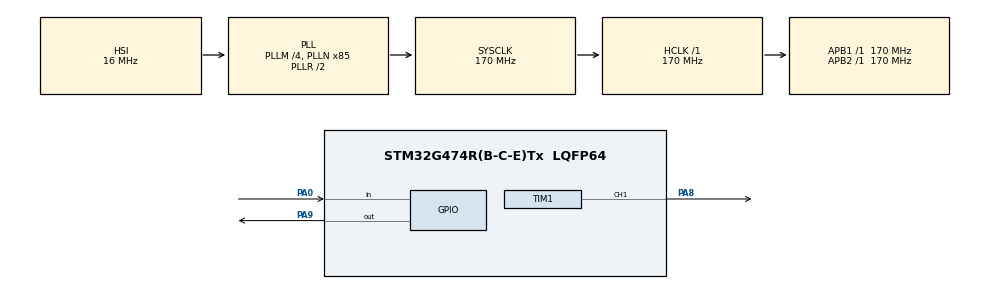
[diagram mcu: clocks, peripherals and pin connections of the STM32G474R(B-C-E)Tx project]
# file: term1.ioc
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Mcu.Family=STM32G4
Mcu.Name=STM32G474R(B-C-E)Tx
Mcu.Package=LQFP64
NVIC.PriorityGroup=NVIC_PRIORITYGROUP_4
PA0.GPIO_PuPd=GPIO_PULLUP
PA0.Signal=GPIO_Input
PA13.GPIO_Label=T_SWDIO
PA13.Signal=SYS_JTMS-SWDIO
PA14.GPIO_Label=T_SWCLK
PA14.Signal=SYS_JTCK-SWCLK
PA2.GPIO_Label=LPUART1_TX [STLINKV3E_VCP_RX]
PA2.Signal=LPUART1_TX
PA3.GPIO_Label=LPUART1_RX [STLINKV3E_VCP_TX]
PA3.Signal=LPUART1_RX
PA8.Signal=S_TIM1_CH1
PA9.Signal=GPIO_Output
PB3.GPIO_Label=T_SWO
PB3.Signal=SYS_JTDO-SWO
PC14-OSC32_IN.GPIO_Label=RCC_OSC32_IN
PC14-OSC32_IN.Signal=RCC_OSC32_IN
PC15-OSC32_OUT.GPIO_Label=RCC_OSC32_OUT
PC15-OSC32_OUT.Signal=RCC_OSC32_OUT
PF0-OSC_IN.GPIO_Label=RCC_OSC_IN
PF0-OSC_IN.Signal=RCC_OSC_IN
PF1-OSC_OUT.GPIO_Label=RCC_OSC_OUT
PF1-OSC_OUT.Signal=RCC_OSC_OUT
ProjectManager.HeapSize=0x200
ProjectManager.StackSize=0x400
ProjectManager.TargetToolchain=STM32CubeIDE
RCC.ADC12Freq_Value=170000000
RCC.ADC345Freq_Value=170000000
RCC.AHBFreq_Value=170000000
RCC.APB1Freq_Value=170000000
RCC.APB1TimFreq_Value=170000000
RCC.APB2Freq_Value=170000000
RCC.APB2TimFreq_Value=170000000
RCC.CortexFreq_Value=170000000
RCC.EXTERNAL_CLOCK_VALUE=12288000
RCC.HCLKFreq_Value=170000000
RCC.HSE_VALUE=24000000
RCC.HSI48_VALUE=48000000
RCC.HSI_VALUE=16000000
RCC.LSE_VALUE=32768
RCC.PLLM=RCC_PLLM_DIV4
RCC.PLLN=85
RCC.RTCClockSelection=RCC_RTCCLKSOURCE_LSE
RCC.SYSCLKFreq_VALUE=170000000
RCC.SYSCLKSource=RCC_SYSCLKSOURCE_PLLCLK
RCC.USBFreq_Value=170000000
RCC.VCOOutputFreq_Value=340000000
SH.S_TIM1_CH1.0=TIM1_CH1,PWM Generation1 CH1
TIM1.Channel-PWM\ Generation1\ CH1=TIM_CHANNEL_1
TIM1.PeriodNoDither=999
TIM1.Prescaler=169
VP_SYS_VS_DBSignals.Mode=DisableDeadBatterySignals
VP_TIM1_VS_ClockSourceINT.Mode=Internal
board=NUCLEO-G474RE

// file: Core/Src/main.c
/* USER CODE BEGIN Header */
/**
  ******************************************************************************
  * @file           : main.c
  * @brief          : Main program body
  ******************************************************************************
  * @attention
  *
  * Copyright (c) 2026 STMicroelectronics.
  * All rights reserved.
  *
  * This software is licensed under terms that can be found in the LICENSE file
  * in the root directory of this software component.
  * If no LICENSE file comes with this software, it is provided AS-IS.
  *
  ******************************************************************************
  */
/* USER CODE END Header */
#include "main.h"

TIM_HandleTypeDef htim1;

/* USER CODE BEGIN PV */
const uint16_t pwm_levels[] = {1000, 750, 500, 250, 100, 0};
uint8_t press_count = 0;
uint8_t last_button_state = GPIO_PIN_SET;
/* USER CODE END PV */

void SystemClock_Config(void);
static void MX_GPIO_Init(void);
static void MX_TIM1_Init(void);

int main(void)
{

  /* MCU Configuration--------------------------------------------------------*/

  /* Reset of all peripherals, Initializes the Flash interface and the Systick. */
  HAL_Init();

  /* Configure the system clock */
  SystemClock_Config();

  /* Initialize all configured peripherals */
  MX_GPIO_Init();
  MX_TIM1_Init();
  /* USER CODE BEGIN 2 */
  // 啟動 TIM1 Channel 1 的 PWM 輸出
  HAL_TIM_PWM_Start(&htim1, TIM_CHANNEL_1);
  // 設定初始亮度為 1000 (全亮)
  __HAL_TIM_SET_COMPARE(&htim1, TIM_CHANNEL_1, pwm_levels[0]);
  /* USER CODE END 2 */

  /* Infinite loop */
    while (1)
    {

      /* USER CODE BEGIN 3 */
      // 讀取 PA0 按鈕狀態
      uint8_t current_button_state = HAL_GPIO_ReadPin(GPIOA, GPIO_PIN_0);

      // 檢測按鈕下緣觸發 (按下瞬間：從 High 變 Low)
      if (last_button_state == GPIO_PIN_SET && current_button_state == GPIO_PIN_RESET)
      {
        HAL_Delay(50); // 防彈跳濾波 (Debounce)
        if (HAL_GPIO_ReadPin(GPIOA, GPIO_PIN_0) == GPIO_PIN_RESET)
        {
          press_count++;

          if (press_count <= 4)
          {
            // 第 1 至 4 次按下：更新 PA8 的 PWM 亮度
            __HAL_TIM_SET_COMPARE(&htim1, TIM_CHANNEL_1, pwm_levels[press_count]);
          }
          else if (press_count == 5)
          {
            // 第 5 次按下：PA8 熄滅，PA9 亮起 (開始澆水)
            __HAL_TIM_SET_COMPARE(&htim1, TIM_CHANNEL_1, pwm_levels[5]); // 0
            HAL_GPIO_WritePin(GPIOA, GPIO_PIN_9, GPIO_PIN_SET);

            // 5 秒內平滑漸亮恢復至 1000 (分 100 階，每階 50ms)
            for (int i = 0; i <= 1000; i += 10)
            {
              __HAL_TIM_SET_COMPARE(&htim1, TIM_CHANNEL_1, i);
              HAL_Delay(50);
            }

            // 澆水完畢：熄滅 PA9，重置計數
            HAL_GPIO_WritePin(GPIOA, GPIO_PIN_9, GPIO_PIN_RESET);
            press_count = 0;
          }
        }
      }

      last_button_state = current_button_state;
    }
    /* USER CODE END 3 */
}

void SystemClock_Config(void)
{
  RCC_OscInitTypeDef RCC_OscInitStruct = {0};
  RCC_ClkInitTypeDef RCC_ClkInitStruct = {0};

  /** Configure the main internal regulator output voltage
  */
  HAL_PWREx_ControlVoltageScaling(PWR_REGULATOR_VOLTAGE_SCALE1_BOOST);

  /** Initializes the RCC Oscillators according to the specified parameters
  * in the RCC_OscInitTypeDef structure.
  */
  RCC_OscInitStruct.OscillatorType = RCC_OSCILLATORTYPE_HSI;
  RCC_OscInitStruct.HSIState = RCC_HSI_ON;
  RCC_OscInitStruct.HSICalibrationValue = RCC_HSICALIBRATION_DEFAULT;
  RCC_OscInitStruct.PLL.PLLState = RCC_PLL_ON;
  RCC_OscInitStruct.PLL.PLLSource = RCC_PLLSOURCE_HSI;
  RCC_OscInitStruct.PLL.PLLM = RCC_PLLM_DIV4;
  RCC_OscInitStruct.PLL.PLLN = 85;
  RCC_OscInitStruct.PLL.PLLP = RCC_PLLP_DIV2;
  RCC_OscInitStruct.PLL.PLLQ = RCC_PLLQ_DIV2;
  RCC_OscInitStruct.PLL.PLLR = RCC_PLLR_DIV2;
  if (HAL_RCC_OscConfig(&RCC_OscInitStruct) != HAL_OK)
  {
    Error_Handler();
  }

  /** Initializes the CPU, AHB and APB buses clocks
  */
  RCC_ClkInitStruct.ClockType = RCC_CLOCKTYPE_HCLK|RCC_CLOCKTYPE_SYSCLK
                              |RCC_CLOCKTYPE_PCLK1|RCC_CLOCKTYPE_PCLK2;
  RCC_ClkInitStruct.SYSCLKSource = RCC_SYSCLKSOURCE_PLLCLK;
  RCC_ClkInitStruct.AHBCLKDivider = RCC_SYSCLK_DIV1;
  RCC_ClkInitStruct.APB1CLKDivider = RCC_HCLK_DIV1;
  RCC_ClkInitStruct.APB2CLKDivider = RCC_HCLK_DIV1;

  if (HAL_RCC_ClockConfig(&RCC_ClkInitStruct, FLASH_LATENCY_4) != HAL_OK)
  {
    Error_Handler();
  }
}

static void MX_TIM1_Init(void)
{

  TIM_ClockConfigTypeDef sClockSourceConfig = {0};
  TIM_MasterConfigTypeDef sMasterConfig = {0};
  TIM_OC_InitTypeDef sConfigOC = {0};
  TIM_BreakDeadTimeConfigTypeDef sBreakDeadTimeConfig = {0};

  htim1.Instance = TIM1;
  htim1.Init.Prescaler = 169;
  htim1.Init.CounterMode = TIM_COUNTERMODE_UP;
  htim1.Init.Period = 999;
  htim1.Init.ClockDivision = TIM_CLOCKDIVISION_DIV1;
  htim1.Init.RepetitionCounter = 0;
  htim1.Init.AutoReloadPreload = TIM_AUTORELOAD_PRELOAD_DISABLE;
  if (HAL_TIM_Base_Init(&htim1) != HAL_OK)
  {
    Error_Handler();
  }
  sClockSourceConfig.ClockSource = TIM_CLOCKSOURCE_INTERNAL;
  if (HAL_TIM_ConfigClockSource(&htim1, &sClockSourceConfig) != HAL_OK)
  {
    Error_Handler();
  }
  if (HAL_TIM_PWM_Init(&htim1) != HAL_OK)
  {
    Error_Handler();
  }
  sMasterConfig.MasterOutputTrigger = TIM_TRGO_RESET;
  sMasterConfig.MasterOutputTrigger2 = TIM_TRGO2_RESET;
  sMasterConfig.MasterSlaveMode = TIM_MASTERSLAVEMODE_DISABLE;
  if (HAL_TIMEx_MasterConfigSynchronization(&htim1, &sMasterConfig) != HAL_OK)
  {
    Error_Handler();
  }
  sConfigOC.OCMode = TIM_OCMODE_PWM1;
  sConfigOC.Pulse = 0;
  sConfigOC.OCPolarity = TIM_OCPOLARITY_HIGH;
  sConfigOC.OCNPolarity = TIM_OCNPOLARITY_HIGH;
  sConfigOC.OCFastMode = TIM_OCFAST_DISABLE;
  sConfigOC.OCIdleState = TIM_OCIDLESTATE_RESET;
  sConfigOC.OCNIdleState = TIM_OCNIDLESTATE_RESET;
  if (HAL_TIM_PWM_ConfigChannel(&htim1, &sConfigOC, TIM_CHANNEL_1) != HAL_OK)
  {
    Error_Handler();
  }
  sBreakDeadTimeConfig.OffStateRunMode = TIM_OSSR_DISABLE;
  sBreakDeadTimeConfig.OffStateIDLEMode = TIM_OSSI_DISABLE;
  sBreakDeadTimeConfig.LockLevel = TIM_LOCKLEVEL_OFF;
  sBreakDeadTimeConfig.DeadTime = 0;
  sBreakDeadTimeConfig.BreakState = TIM_BREAK_DISABLE;
  sBreakDeadTimeConfig.BreakPolarity = TIM_BREAKPOLARITY_HIGH;
  sBreakDeadTimeConfig.BreakFilter = 0;
  sBreakDeadTimeConfig.BreakAFMode = TIM_BREAK_AFMODE_INPUT;
  sBreakDeadTimeConfig.Break2State = TIM_BREAK2_DISABLE;
  sBreakDeadTimeConfig.Break2Polarity = TIM_BREAK2POLARITY_HIGH;
  sBreakDeadTimeConfig.Break2Filter = 0;
  sBreakDeadTimeConfig.Break2AFMode = TIM_BREAK_AFMODE_INPUT;
  sBreakDeadTimeConfig.AutomaticOutput = TIM_AUTOMATICOUTPUT_DISABLE;
  if (HAL_TIMEx_ConfigBreakDeadTime(&htim1, &sBreakDeadTimeConfig) != HAL_OK)
  {
    Error_Handler();
  }
  HAL_TIM_MspPostInit(&htim1);

}

static void MX_GPIO_Init(void)
{
  GPIO_InitTypeDef GPIO_InitStruct = {0};

  /* GPIO Ports Clock Enable */
  __HAL_RCC_GPIOC_CLK_ENABLE();
  __HAL_RCC_GPIOF_CLK_ENABLE();
  __HAL_RCC_GPIOA_CLK_ENABLE();
  __HAL_RCC_GPIOB_CLK_ENABLE();

  /*Configure GPIO pin Output Level */
  HAL_GPIO_WritePin(GPIOA, GPIO_PIN_9, GPIO_PIN_RESET);

  /*Configure GPIO pin : PA0 */
  GPIO_InitStruct.Pin = GPIO_PIN_0;
  GPIO_InitStruct.Mode = GPIO_MODE_INPUT;
  GPIO_InitStruct.Pull = GPIO_PULLUP;
  HAL_GPIO_Init(GPIOA, &GPIO_InitStruct);

  /*Configure GPIO pins : LPUART1_TX_Pin LPUART1_RX_Pin */
  GPIO_InitStruct.Pin = LPUART1_TX_Pin|LPUART1_RX_Pin;
  GPIO_InitStruct.Mode = GPIO_MODE_AF_PP;
  GPIO_InitStruct.Pull = GPIO_NOPULL;
  GPIO_InitStruct.Speed = GPIO_SPEED_FREQ_LOW;
  GPIO_InitStruct.Alternate = GPIO_AF12_LPUART1;
  HAL_GPIO_Init(GPIOA, &GPIO_InitStruct);

  /*Configure GPIO pin : PA9 */
  GPIO_InitStruct.Pin = GPIO_PIN_9;
  GPIO_InitStruct.Mode = GPIO_MODE_OUTPUT_PP;
  GPIO_InitStruct.Pull = GPIO_NOPULL;
  GPIO_InitStruct.Speed = GPIO_SPEED_FREQ_LOW;
  HAL_GPIO_Init(GPIOA, &GPIO_InitStruct);

}

void Error_Handler(void)
{
  __disable_irq();
  while (1)
  {
  }
}
